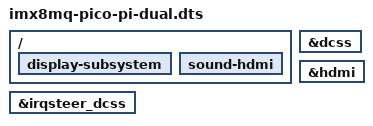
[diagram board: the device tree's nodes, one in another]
/*
 * Copyright 2018 Technexion Ltd.
 *
 * Author: Richard Hu <richard.hu@technexion.com>, Po Cheng <po.cheng@technexion.com>
 *
 * This program is free software; you can redistribute it and/or
 * modify it under the terms of the GNU General Public License
 * as published by the Free Software Foundation; either version 2
 * of the License, or (at your option) any later version.
 *
 * This program is distributed in the hope that it will be useful,
 * but WITHOUT ANY WARRANTY; without even the implied warranty of
 * MERCHANTABILITY or FITNESS FOR A PARTICULAR PURPOSE.  See the
 * GNU General Public License for more details.
 */
#include "imx8mq-pico-pi-lcdif-ili9881c.dts"

/ {
	display-subsystem {
		status = "okay";
	};

	sound-hdmi {
		status = "okay";
	};
};

&irqsteer_dcss {
	status = "okay";
};

&dcss {
	status = "okay";
};

&hdmi {
	status = "okay";
};

#if 0
// liutest
&i2c2 {
	status = "disabled";
};

&i2c3 {
	status = "disabled";
};

/*
&pwm1
{
	status = "disabled";
};
*/

&pcie1  {
	status = "disabled";
};

/*
&fec1   {
	status = "disabled";
};
*/
#endif

